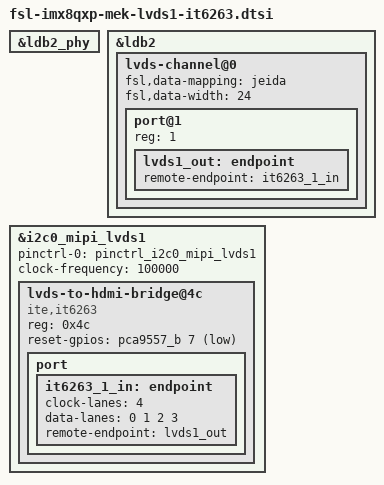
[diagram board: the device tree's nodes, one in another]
/*
 * Copyright 2017 NXP
 *
 * This program is free software; you can redistribute it and/or
 * modify it under the terms of the GNU General Public License
 * as published by the Free Software Foundation; either version 2
 * of the License, or (at your option) any later version.
 *
 * This program is distributed in the hope that it will be useful,
 * but WITHOUT ANY WARRANTY; without even the implied warranty of
 * MERCHANTABILITY or FITNESS FOR A PARTICULAR PURPOSE.  See the
 * GNU General Public License for more details.
 */

&ldb2_phy {
	status = "okay";
};

&ldb2 {
	status = "okay";

	lvds-channel@0 {
		fsl,data-mapping = "jeida";
		fsl,data-width = <24>;
		status = "okay";

		port@1 {
			reg = <1>;

			lvds1_out: endpoint {
				remote-endpoint = <&it6263_1_in>;
			};
		};
	};
};

&i2c0_mipi_lvds1 {
	#address-cells = <1>;
	#size-cells = <0>;
	pinctrl-names = "default";
	pinctrl-0 = <&pinctrl_i2c0_mipi_lvds1>;
	clock-frequency = <100000>;
	status = "okay";

	lvds-to-hdmi-bridge@4c {
		compatible = "ite,it6263";
		reg = <0x4c>;
		reset-gpios = <&pca9557_b 7 GPIO_ACTIVE_LOW>;

		port {
			it6263_1_in: endpoint {
				clock-lanes = <4>;
				data-lanes = <0 1 2 3>;
				remote-endpoint = <&lvds1_out>;
			};
		};
	};
};
